# FSS0_FSAS_0_FSAS_CFG register map
Vendor: Texas Instruments
Peripheral module from a debugger description file (folder J722S).
Registers are 32-bit, access not given, reset 0x0 unless marked. A register's access mark holds for its fields unless they carry their own. Offsets are as the file gives them; lines under a group give offsets from that group; [hi:lo] are bit positions; {n}, {i} and the like mark numbered series; 'fields as' and 'values as' point back to an identical list; <NAME> marks a mode.

## FSS0_FSAS_0_FSAS_CFG
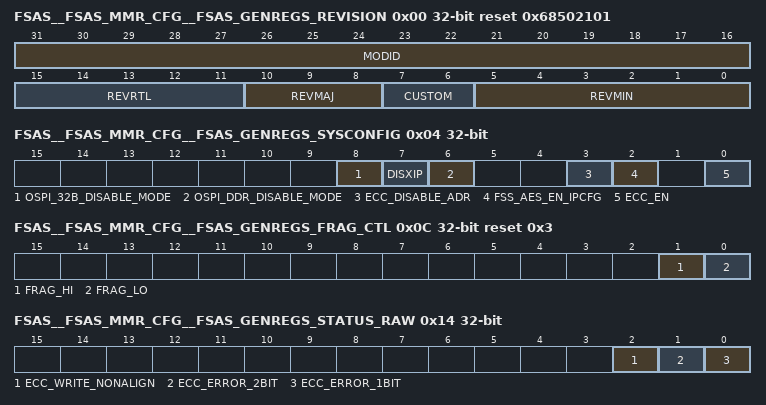
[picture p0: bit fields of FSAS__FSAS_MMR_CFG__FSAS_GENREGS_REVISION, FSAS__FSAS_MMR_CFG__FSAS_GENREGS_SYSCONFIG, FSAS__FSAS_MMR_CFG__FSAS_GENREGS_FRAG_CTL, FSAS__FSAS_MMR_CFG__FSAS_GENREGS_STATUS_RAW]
0x00 FSAS__FSAS_MMR_CFG__FSAS_GENREGS_REVISION ro reset 0x68502101 — IP Revision Identifier (X.Y.R) Used by software to track features, bugs, and compatibility
  [31:16] MODID — Module ID field
  [15:11] REVRTL — RTL revision. Will vary depending on release.
  [10:8] REVMAJ — Major revision
  [7:6] CUSTOM
  [5:0] REVMIN — Minor revision
0x04 FSAS__FSAS_MMR_CFG__FSAS_GENREGS_SYSCONFIG access per field — Controls various parameters of the cotroller state.
  [8] OSPI_32B_DISABLE_MODE rw — 0 OSPI 32bit mode enabled. 1 OSPI 32bit mode disabled
  [7] DISXIP rw — 0 XIP Prefetch Enabled. 1 XIP prefetch disabled
  [6] OSPI_DDR_DISABLE_MODE rw — 0 OSPI DDR mode enabled. 1 OSPI DDR mode disabled
  [3] ECC_DISABLE_ADR rw — 0 Block address within ECC calculation, 1 Block address not within ECC calculation
  [2] FSS_AES_EN_IPCFG ro — 1 select security, 0 disable security
  [0] ECC_EN rw — 0 ECC disabled. 1 ECC enabled
0x08 FSAS__FSAS_MMR_CFG__FSAS_GENREGS_FRAG_ADR rw — This FRAG_ADR is the address of a request that frag_hi or frag_lo boundary occurs
  [31:0] FRAG_ADDR — This address is used to determine the boundary of frag_hi and flag_lo
0x0C FSAS__FSAS_MMR_CFG__FSAS_GENREGS_FRAG_CTL rw reset 0x3 — The FRAG_CTL determins which frag region is fragmented
  [1] FRAG_HI — When set any address greater than or equal to frag_addr will be fragmented to 16 bits
  [0] FRAG_LO — When set any address less than frag_addr will be fragmented to 16 bits
0x10 FSAS__FSAS_MMR_CFG__FSAS_GENREGS_EOI rw — The End of Interrupt (EOI) MISC Register allows the CPU to acknowledge completion of an interrupt by writing to the EOI for MISC interrupt sources. An eoi_write signal will be generated and another interrupt will be triggered if interrupt sources remain. This register will be reset one cycle after it has been written to.
  [0] EOI_VECTOR — Write with bit position of targeted interrupt. (E.g. Ext FSS ECC is bit 0). Upon write, level interrupt will clear and if un-serviced will issue another pulse interrupt
0x14 FSAS__FSAS_MMR_CFG__FSAS_GENREGS_STATUS_RAW — The IRQ_STATUS_RAW register allows the interrupt sources to be manually set when writing a 1 to a specific bit. Write 0: No action Write 1: Set event Read 0: No event pending Read 1: Event pending
  [2] ECC_WRITE_NONALIGN — Write is not aligned to 32B boundary or not a multiple of 32B (access R/W1TS)
  [1] ECC_ERROR_2BIT — ECC error on 2 bits. Not correctable (access R/W1TS)
  [0] ECC_ERROR_1BIT — ECC error on 1 bits. correctable (access R/W1TS)
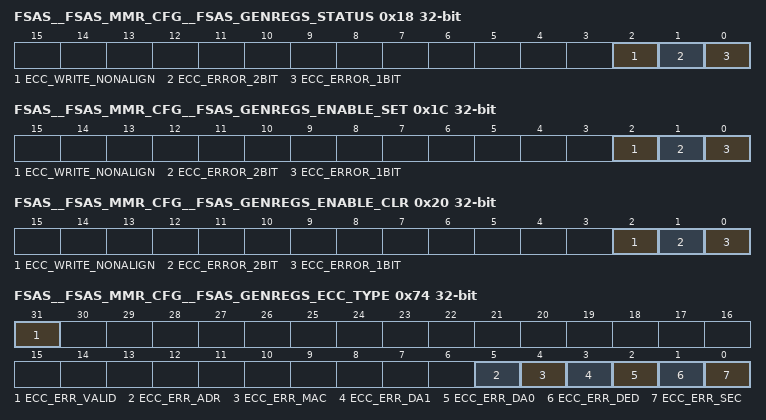
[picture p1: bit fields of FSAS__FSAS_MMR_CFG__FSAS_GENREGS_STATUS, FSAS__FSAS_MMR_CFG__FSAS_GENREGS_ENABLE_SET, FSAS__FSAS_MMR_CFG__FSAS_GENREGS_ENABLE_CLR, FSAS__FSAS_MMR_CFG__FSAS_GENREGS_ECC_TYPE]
0x18 FSAS__FSAS_MMR_CFG__FSAS_GENREGS_STATUS — The IRQ_STATUS register allows the interrupt sources to be manually cleared when writing a 1 to a specific bit. Write 0: No action Write 1: Clear event Read 0: No event pending Read 1: Event pending
  [2] ECC_WRITE_NONALIGN — Write is not aligned to 32B boundary or not a multiple of 32B (access R/W1TC)
  [1] ECC_ERROR_2BIT — ECC error on 2 bits. Not correctable (access R/W1TC)
  [0] ECC_ERROR_1BIT — ECC error on 1 bits. correctable (access R/W1TC)
0x1C FSAS__FSAS_MMR_CFG__FSAS_GENREGS_ENABLE_SET — The IRQ_ENABLE_SET register allows the interrupt sources to be manually enabled when writing a 1 to a specific bit. Write 0: No action Write 1: Enable event Read 0: Event is disabled Read 1: Event is enabled
  fields as FSAS__FSAS_MMR_CFG__FSAS_GENREGS_STATUS_RAW
0x20 FSAS__FSAS_MMR_CFG__FSAS_GENREGS_ENABLE_CLR — The IRQ_ENABLE_CLR register allows the interrupt sources to be manually disabled when writing a 1 to a specific bit. Write 0: No action Write 1: Disable event Read 0: Event is disabled Read 1: Event is enabled
  fields as FSAS__FSAS_MMR_CFG__FSAS_GENREGS_STATUS
0x30 FSAS__FSAS_MMR_CFG__FSAS_GENREGS_ECC_RGSTRT rw — This defines the start of the ECC region in 4KBytes steps.
  [19:0] R_START — This defines the start of the ECC region in 4KBytes steps. Address start = {start[19:0], 0x000} 0x0 means the start is 0x0000_0000 0x1 means the start is 0x0000_1000 0xA means the start is 0x0000_A000 Note the offset + size should be &#60;= 4GBytes, wrap around is not supported.
0x34 FSAS__FSAS_MMR_CFG__FSAS_GENREGS_ECC_RGSIZ rw — This defines the size of the ECC region in 4KBytes steps.
  [19:0] R_SIZE — This defines the size of the ECC region in 4KBytes steps 0x0 means the size is zero and disabled 0x1 means the size is 4KBytes 0xA means the size is 40KBytes 0xF_FFFF means the size is 4GBytes Note the offset + size should be &#60;= 4GBytes, wrap around is not supported.
0x70 FSAS__FSAS_MMR_CFG__FSAS_GENREGS_ECC_BLOCK_ADR ro — The ERR_ECC_BLOCK_ADR register holds the current top of stack ECC error block address, this is only valid when the ecc_err_valid is set
  [31:5] ECC_ERROR_BLOCK_ADDR — ECC 32 byte aligned block address
0x74 FSAS__FSAS_MMR_CFG__FSAS_GENREGS_ECC_TYPE — The ERR_ECC_TYPE register holds the current top of stack ECC error info, this is only valid when the ecc_err_valid is set
  [31] ECC_ERR_VALID — When set indicates that there is valid ECC error information available, Writing a one to this register will pop the top of the stack (access R/W1TC)
  [5] ECC_ERR_ADR ro — When set indicates that there was a single error detected within the address field
  [4] ECC_ERR_MAC ro — When set indicates that there was a single error detected within the MAC field
  [3] ECC_ERR_DA1 ro — When set indicates that there was a single error detected within the High Data word
  [2] ECC_ERR_DA0 ro — When set indicates that there was a single error detected within the Low Data word
  [1] ECC_ERR_DED ro — When set indicates that there was a double error detected for the block
  [0] ECC_ERR_SEC ro — hen set indicates that there was a single error detected for the block
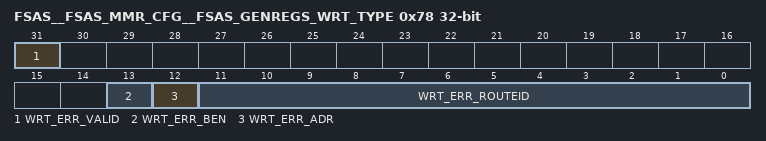
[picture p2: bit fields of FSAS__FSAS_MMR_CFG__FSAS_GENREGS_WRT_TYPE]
0x78 FSAS__FSAS_MMR_CFG__FSAS_GENREGS_WRT_TYPE — The ERR_WRT_TYPE register holds the current top of stack write error info. this is only valid when the wrt_err_valid is set
  [31] WRT_ERR_VALID — When set indicates that there is valid write error information available, Writing a one to this register will pop the top of the stack (access R/W1TC)
  [13] WRT_ERR_BEN ro — When set indicates that there was a write error due to a non-contiguous byte enables
  [12] WRT_ERR_ADR ro — When set indicates that there was a write error due to a non-aligned address
  [11:0] WRT_ERR_ROUTEID ro — Indicates the Route ID for the Initiator that caused the write error
